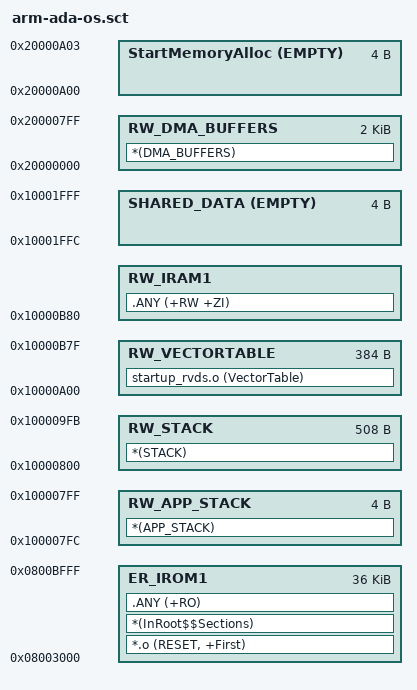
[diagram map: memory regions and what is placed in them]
; *************************************************************
; *** Scatter-Loading Description File generated by uVision ***
; *************************************************************

LR_IROM1 0x8003000 0x9000  
{    ; load region size_region (about 36K of code)

  ER_IROM1 0x8003000 0x9000  
  {  ; load address = execution address
   *.o (RESET, +First)
   *(InRoot$$Sections)
   .ANY (+RO)
  }
  
  RW_STACK 0x10000800 0x1FC {
    *(STACK)
  }
  
  RW_APP_STACK 0x10000800-0x4 0x4 {
    *(APP_STACK);
  }
  
  RW_VECTORTABLE 0x10000A00 0x180 
  {  ; Vector Table (around 400 bytes)
    startup_rvds.o (VectorTable)
  }

  RW_IRAM1 0x10000A00+0x180 ; Start of Data RAM  
  {  ; RW data (start after vector table , 4K of ram)
   .ANY (+RW +ZI)
  }
  
  RW_DMA_BUFFERS 0x20000000 0x800 { ; DMA buffer, 2K
	*(DMA_BUFFERS)
  }
  
  StartMemoryAlloc 0x20000A00 EMPTY 4 {}
  SHARED_DATA 0x10001FFC EMPTY 4 {}
}

